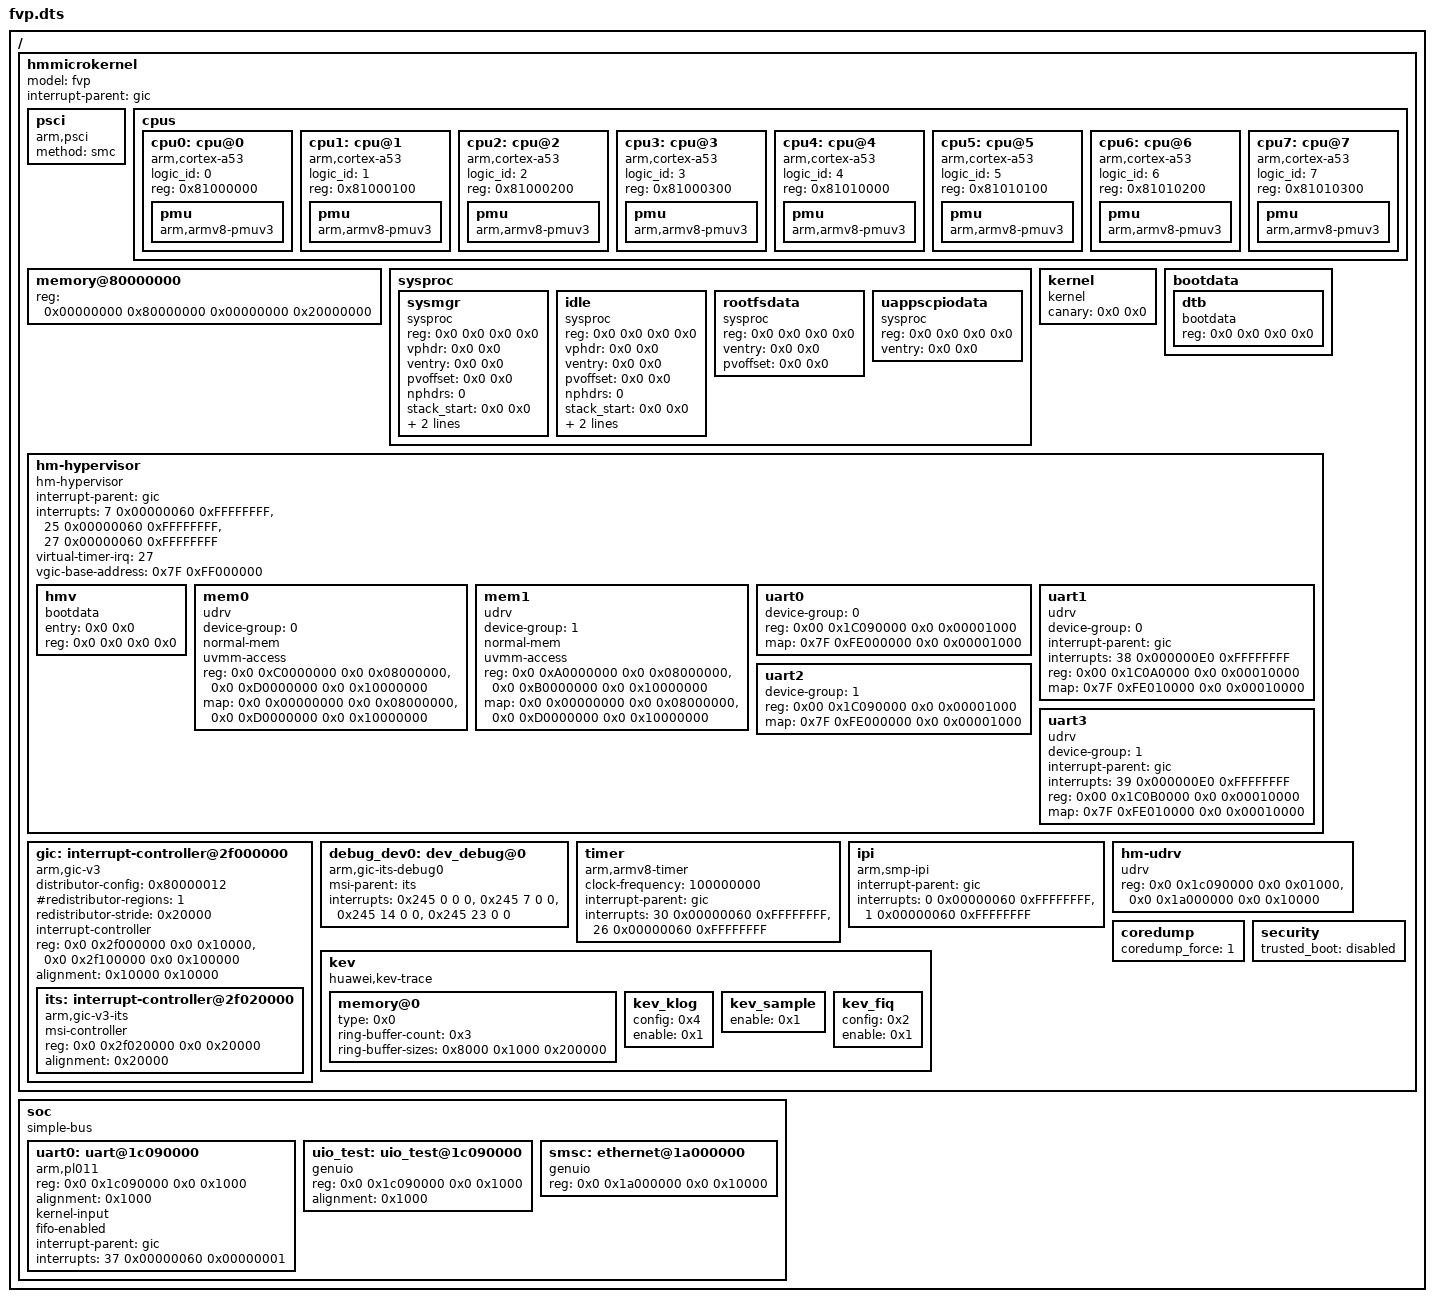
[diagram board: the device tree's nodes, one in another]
/dts-v1/;
/ { #address-cells = <2>; #size-cells = <2>; hmmicrokernel {
	model = "fvp";
	interrupt-parent = <&gic>;
	#address-cells = <2>;
	#size-cells = <2>;

	psci {
		compatible = "arm,psci";
		method = "smc";
	};

	cpus {
		#address-cells = <1>;
		#size-cells = <0>;
		cpu0: cpu@0 {
			compatible = "arm,cortex-a53", "arm,armv8";
			device_type = "cpu";
			logic_id = <0>;
			reg = <0x81000000>;
			pmu {
				compatible = "arm,armv8-pmuv3";
			};

		};
		cpu1: cpu@1 {
			compatible = "arm,cortex-a53", "arm,armv8";
			device_type = "cpu";
			logic_id = <1>;
			reg = <0x81000100>;
			pmu {
				compatible = "arm,armv8-pmuv3";
			};

		};
		cpu2: cpu@2 {
			compatible = "arm,cortex-a53", "arm,armv8";
			device_type = "cpu";
			logic_id = <2>;
			reg = <0x81000200>;
			pmu {
				compatible = "arm,armv8-pmuv3";
			};

		};
		cpu3: cpu@3 {
			compatible = "arm,cortex-a53", "arm,armv8";
			device_type = "cpu";
			logic_id = <3>;
			reg = <0x81000300>;
			pmu {
				compatible = "arm,armv8-pmuv3";
			};

		};
		cpu4: cpu@4 {
			compatible = "arm,cortex-a53", "arm,armv8";
			device_type = "cpu";
			logic_id = <4>;
			reg = <0x81010000>;
			pmu {
				compatible = "arm,armv8-pmuv3";
			};

		};
		cpu5: cpu@5 {
			compatible = "arm,cortex-a53", "arm,armv8";
			device_type = "cpu";
			logic_id = <5>;
			reg = <0x81010100>;
			pmu {
				compatible = "arm,armv8-pmuv3";
			};

		};
		cpu6: cpu@6 {
			compatible = "arm,cortex-a53", "arm,armv8";
			device_type = "cpu";
			logic_id = <6>;
			reg = <0x81010200>;
			pmu {
				compatible = "arm,armv8-pmuv3";
			};

		};
		cpu7: cpu@7 {
			compatible = "arm,cortex-a53", "arm,armv8";
			device_type = "cpu";
			logic_id = <7>;
			reg = <0x81010300>;
			pmu {
				compatible = "arm,armv8-pmuv3";
			};

		};
	};

	memory@80000000 {
		device_type = "memory";
		reg = <0x00000000 0x80000000 0x00000000 0x20000000>;
	};

	sysproc {
		#address-cells = <2>;
		#size-cells = <2>;
		sysmgr {
			compatible = "sysproc", "sysmgr";
			/* filled by bootloader */
			reg      = <0x0 0x0 0x0 0x0>;
			vphdr    = <0x0 0x0>;
			ventry   = <0x0 0x0>;
			pvoffset = <0x0 0x0>;
			nphdrs   = <0>;
			stack_start = <0x0 0x0>;
			stack_end = <0x0 0x0>;
			canary = <0x0 0x0>;
		};
		idle {
			compatible = "sysproc", "idle";
			/* filled by bootloader */
			reg      = <0x0 0x0 0x0 0x0>;
			vphdr    = <0x0 0x0>;
			ventry   = <0x0 0x0>;
			pvoffset = <0x0 0x0>;
			nphdrs   = <0>;
			stack_start = <0x0 0x0>;
			stack_end = <0x0 0x0>;
			canary = <0x0 0x0>;
		};
		rootfsdata {
			compatible = "sysproc", "rootfs";
			/* filled by bootloader */
			reg      = <0x0 0x0 0x0 0x0>;
			ventry   = <0x0 0x0>;
			pvoffset = <0x0 0x0>;
		};
		uappscpiodata {
			compatible = "sysproc", "uappscpio";
			/* filled by bootloader */
			reg      = <0x0 0x0 0x0 0x0>;
			ventry   = <0x0 0x0>;
		};
	};

	kernel {
		compatible = "kernel";
		/* filled by bootloader */
		canary = <0x0 0x0>;
	};

	bootdata {
		#address-cells = <2>;
		#size-cells = <2>;
		dtb {
			compatible = "bootdata", "dtb";
			/* filled by bootloader */
			reg = <0x0 0x0 0x0 0x0>;
		};
	};

	hm-hypervisor {
		compatible = "hm-hypervisor";
		#address-cells = <2>;
		#size-cells = <2>;

		interrupt-parent = <&gic>;
		interrupts = < 7 0x00000060 0xFFFFFFFF>,
			     <25 0x00000060 0xFFFFFFFF>,
			     <27 0x00000060 0xFFFFFFFF>;

		virtual-timer-irq = <27>;
		vgic-base-address = <0x7F 0xFF000000>;

		hmv {
			compatible = "bootdata";
			/* filled by bootloader */
			entry = <0x0 0x0>;
			reg = <0x0 0x0 0x0 0x0>;
		};

		/* for vm0*/
		mem0 {
			device-group = <0>;
			compatible = "udrv";
			normal-mem;
			uvmm-access;
			reg = <0x0 0xC0000000 0x0 0x08000000>,
			      <0x0 0xD0000000 0x0 0x10000000>;
			map = <0x0 0x00000000 0x0 0x08000000>,
			      <0x0 0xD0000000 0x0 0x10000000>;
		};

		/* for vm1*/
		mem1 {
			device-group = <1>;
			compatible = "udrv";
			normal-mem;
			uvmm-access;
			reg = <0x0 0xA0000000 0x0 0x08000000>,
			      <0x0 0xB0000000 0x0 0x10000000>;
			map = <0x0 0x00000000 0x0 0x08000000>,
			      <0x0 0xD0000000 0x0 0x10000000>;
		};

		uart0 {
			device-group = <0>;
			reg = <0x00 0x1C090000 0x0 0x00001000>;
			map = <0x7F 0xFE000000 0x0 0x00001000>;
		};

		uart1 {
			device-group = <0>;
			compatible = "udrv";
			interrupt-parent = <&gic>;
			interrupts = <38 0x000000E0 0xFFFFFFFF>;
			reg = <0x00 0x1C0A0000 0x0 0x00010000>;
			map = <0x7F 0xFE010000 0x0 0x00010000>;
		};

		uart2 {
			device-group = <1>;
			reg = <0x00 0x1C090000 0x0 0x00001000>;
			map = <0x7F 0xFE000000 0x0 0x00001000>;
		};

		uart3 {
			device-group = <1>;
			compatible = "udrv";
			interrupt-parent = <&gic>;
			interrupts = <39 0x000000E0 0xFFFFFFFF>;
			reg = <0x00 0x1C0B0000 0x0 0x00010000>;
			map = <0x7F 0xFE010000 0x0 0x00010000>;
		};
	};

	/* See Documentation/dts-gic.md for interrupts and distributor_config */
	gic: interrupt-controller@2f000000 {
		compatible = "arm,gic-v3";

		#address-cells = <2>;
		#size-cells = <2>;

		/* Enable group 0, Group1NS, Group1S, ARE_NS, ARE_S,
		 * Split EOI and Deactive mode */
		distributor-config = <0x80000012>;

		#interrupt-cells = <3>;
		#redistributor-regions = <1>;
		redistributor-stride = <0x20000>;
		interrupt-controller;

		reg =	<0x0 0x2f000000 0x0 0x10000>,	/* GICD */
			<0x0 0x2f100000 0x0 0x100000>;	/* GICR */
		alignment = <0x10000 0x10000>;

		its: interrupt-controller@2f020000 {
			compatible = "arm,gic-v3-its";
			msi-controller;
			reg = <0x0 0x2f020000 0x0 0x20000>;
			alignment = <0x20000>;
			#interrupt-cells = <4>;
		};
	};

	debug_dev0:dev_debug@0 {
		compatible = "arm,gic-its-debug0";
		msi-parent = <&its>;
		interrupts = <0x245 0 0 0>,
			     <0x245 7 0 0>,
			     <0x245 14 0 0>,
			     <0x245 23 0 0>;
	};

	timer {
		compatible = "arm,armv8-timer";
		clock-frequency = <100000000>;
		/* interrupt settings */
		interrupt-parent = <&gic>;

		/* PPI 30: Non-secure physical timer
		 * PPI 26: Non-secure hypervisor timer
		 * level triggered, hwprio:0x60 */
		interrupts = <30 0x00000060 0xFFFFFFFF>,
			     <26 0x00000060 0xFFFFFFFF>;
	};

	ipi {
		/* smp ipi */
		compatible = "arm,smp-ipi";

		interrupt-parent = <&gic>;

		/* interrupt settings:
		 * 1st cell: real hardware irq number
		 *     ARM recommendation: ID 0-7 for Non-Secure;
		 *                         ID 8-15 for Secure Interrupt
		 * 2nd cell: interrupt config
		 *     bit [27:26]: Group setting
		 *     bit [24]: Trigger Type
		 *     bit [23:8]: Reserved
		 *     bit [7:0]: Priority
		 * 3rd cell: interrupt target config
		 *     Warning: Send to all cpus by default
		 */
		interrupts =	<0 0x00000060 0xFFFFFFFF>, /* IPI_RESCHEDULE */
				<1 0x00000060 0xFFFFFFFF>; /* IPI_CALL_FUNC */
	};

	kev {
		compatible = "huawei,kev-trace";

		memory@0 {
			type = <0x0>;
			ring-buffer-count = <0x3>;
			/*
			 * Only ring buffer DATA sizes. Memory head and ring
			 * buffer heads are not included.
			 * ring buffer 0: 32K
			 * ring buffer 1: 4K
			 * ring buffer 2: 2M (klog)
			 */
			ring-buffer-sizes = <0x8000 0x1000 0x200000>;
		};
		kev_klog {
			config = <0x4>;
			enable = <0x1>;
		};
		kev_sample {
			enable = <0x1>;
		};
		kev_fiq {
			config = <0x2>;
			enable = <0x1>;
		};
	};

	hm-udrv {
		compatible = "udrv";
		reg = <0x0 0x1c090000 0x0 0x01000>,
		      <0x0 0x1a000000 0x0 0x10000>;
	};

	coredump {
		coredump_force = <1>;
	};

	security {
		trusted_boot = "disabled";
	};
	};

	soc {
		compatible = "simple-bus";
		#address-cells = <2>;
		#size-cells = <2>;
		ranges;

		uart0: uart@1c090000 {
			compatible = "arm,pl011", "arm,pl011,uart";
			reg = <0x0 0x1c090000 0x0 0x1000>;
			alignment = <0x1000>;

			kernel-input;
			fifo-enabled;
			interrupt-parent=<&gic>;
			interrupts=<37 0x00000060 0x00000001>;
		};

		uio_test: uio_test@1c090000 {
			compatible = "genuio";
			reg = <0x0 0x1c090000 0x0 0x1000>;
			alignment = <0x1000>;
		};

		smsc: ethernet@1a000000 {
			compatible = "genuio";
			reg = <0x0 0x1a000000  0x0 0x10000>;
		};
	};
};
